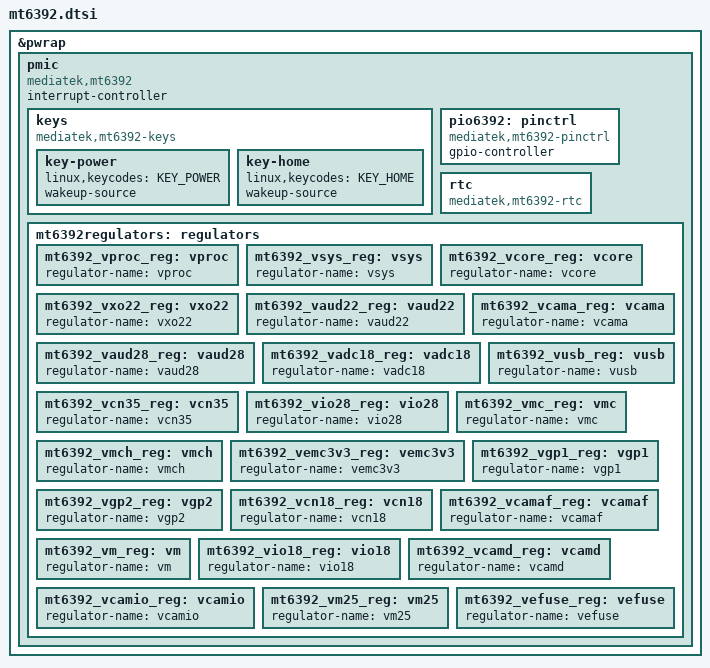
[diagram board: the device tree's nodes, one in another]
// SPDX-License-Identifier: GPL-2.0
/*
 * Copyright (c) 2019 MediaTek Inc.
 * Copyright (c) 2024 Val Packett <val@packett.cool>
 */

#include <dt-bindings/input/input.h>

&pwrap {
	pmic: pmic {
		compatible = "mediatek,mt6392", "mediatek,mt6323";
		interrupt-controller;
		#interrupt-cells = <2>;

		keys {
			compatible = "mediatek,mt6392-keys";

			key-power {
				linux,keycodes = <KEY_POWER>;
				wakeup-source;
			};

			key-home {
				linux,keycodes = <KEY_HOME>;
				wakeup-source;
			};
		};

		pio6392: pinctrl {
			compatible = "mediatek,mt6392-pinctrl";

			gpio-controller;
			#gpio-cells = <2>;
		};

		rtc {
			compatible = "mediatek,mt6392-rtc",
				"mediatek,mt6323-rtc";
		};

		mt6392regulators: regulators {
			mt6392_vproc_reg: vproc {
				regulator-name = "vproc";
			};

			mt6392_vsys_reg: vsys {
				regulator-name = "vsys";
			};

			mt6392_vcore_reg: vcore {
				regulator-name = "vcore";
			};

			mt6392_vxo22_reg: vxo22 {
				regulator-name = "vxo22";
			};

			mt6392_vaud22_reg: vaud22 {
				regulator-name = "vaud22";
			};

			mt6392_vcama_reg: vcama {
				regulator-name = "vcama";
			};

			mt6392_vaud28_reg: vaud28 {
				regulator-name = "vaud28";
			};

			mt6392_vadc18_reg: vadc18 {
				regulator-name = "vadc18";
			};

			mt6392_vcn35_reg: vcn35 {
				regulator-name = "vcn35";
			};

			mt6392_vio28_reg: vio28 {
				regulator-name = "vio28";
			};

			mt6392_vusb_reg: vusb {
				regulator-name = "vusb";
			};

			mt6392_vmc_reg: vmc {
				regulator-name = "vmc";
			};

			mt6392_vmch_reg: vmch {
				regulator-name = "vmch";
			};

			mt6392_vemc3v3_reg: vemc3v3 {
				regulator-name = "vemc3v3";
			};

			mt6392_vgp1_reg: vgp1 {
				regulator-name = "vgp1";
			};

			mt6392_vgp2_reg: vgp2 {
				regulator-name = "vgp2";
			};

			mt6392_vcn18_reg: vcn18 {
				regulator-name = "vcn18";
			};

			mt6392_vcamaf_reg: vcamaf {
				regulator-name = "vcamaf";
			};

			mt6392_vm_reg: vm {
				regulator-name = "vm";
			};

			mt6392_vio18_reg: vio18 {
				regulator-name = "vio18";
			};

			mt6392_vcamd_reg: vcamd {
				regulator-name = "vcamd";
			};

			mt6392_vcamio_reg: vcamio {
				regulator-name = "vcamio";
			};

			mt6392_vm25_reg: vm25 {
				regulator-name = "vm25";
			};

			mt6392_vefuse_reg: vefuse {
				regulator-name = "vefuse";
			};
		};
	};
};
